# NUC1xx_registers register map
File version: 0.1
CPU: 
Registers are 32-bit, read-write, reset 0x0 unless marked. A register's access mark holds for its fields unless they carry their own. Offsets are from the block's base; [hi:lo] are bit positions; lines under a group give offsets from that group; {n}, {i} and the like mark numbered series.

## PDMA0 — Registers group
Base 0x50008000
Same registers: PDMA{n} {0x50008000+0x100*n} (n=1..8)
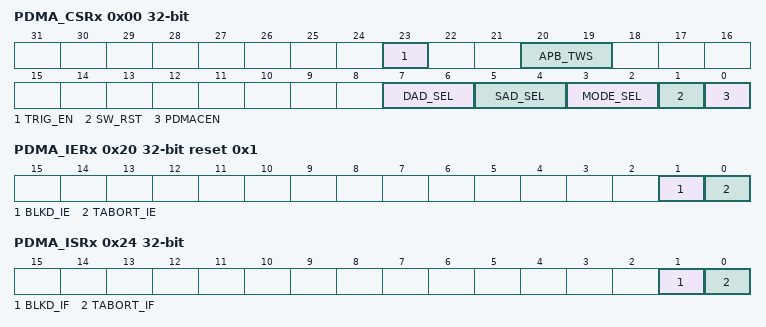
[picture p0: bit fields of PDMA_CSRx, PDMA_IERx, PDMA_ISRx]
0x00 PDMA_CSRx — PDMA Control and Status Register CHx
  [23] TRIG_EN — Trig_EN 0 = No effect. 1 = Enable PDMA data read or write transfer. Note: When PDMA transfer completed, this bit will be cleared automatically. If the bus error occurs, all PDMA transfer will be stopped. Software must reset all PDMA channel, and then trigger again.
  [20:19] APB_TWS — Peripheral transfer Width Select 00 = One word (32 bits) is transferred for every PDMA operation. 01 = One byte (8 bits) is transferred for every PDMA operation. 10 = One half-word (16 bits) is transferred for every PDMA operation. 11 = Reserved. Note: This field is meaningful only when MODE_SEL is IP to Memory mode (APB-to-Memory) or Memory to IP mode (Memory-to-APB).
  [7:6] DAD_SEL — Transfer Destination Address Direction Select 00 = Transfer Destination address is incremented successively. 01 = Reserved. 10 = Transfer Destination address is fixed (This feature can be used when data where transferred from multiple sources to a single destination). 11 = Reserved.
  [5:4] SAD_SEL — Transfer Source Address Direction Select 00 = Transfer Source address is incremented successively. 01 = Reserved. 10 = Transfer Source address is fixed (This feature can be used when data where transferred from a single source to multiple destinations). 11 = Reserved.
  [3:2] MODE_SEL — PDMA Mode Select 00 = Memory to Memory mode (Memory-to-Memory). 01 = IP to Memory mode (APB-to-Memory). 10 = Memory to IP mode (Memory-to-APB).
  [1] SW_RST — Software Engine Reset 0 = Writing 0 to this bit has no effect. 1 = Writing 1 to this bit will reset the internal state machine and pointers. The contents of control register will not be cleared. This bit will auto clear after few clock cycles.
  [0] PDMACEN — PDMA Channel Enable Setting this bit to 1 enables PDMA's operation. If this bit is cleared, PDMA will ignore all PDMA request and force Bus Master into IDLE state. Note: SW_RST(PDMA_CSRx[1], x= 0~8) will clear this bit.
0x04 PDMA_SARx — PDMA Transfer Source Address Register CHx
  [31:0] PDMA_SAR — PDMA Transfer Source Address Register This field indicates a 32-bit source address of PDMA. Note : The source address must be word alignment
0x08 PDMA_DARx — PDMA Transfer Destination Address Register CHx
  [31:0] PDMA_DAR — PDMA Transfer Destination Address Register This field indicates a 32-bit destination address of PDMA. Note : The destination address must be word alignment
0x0C PDMA_BCRx — PDMA Transfer Byte Count Register CHx
  [15:0] PDMA_BCR — PDMA Transfer Byte Count Register This field indicates a 16-bit transfer byte count of PDMA.it must be word alignment.
0x10 PDMA_POINTx ro — PDMA Internal Buffer Pointer Register CHx
  [3:0] PDMA_POINT — PDMA Internal Buffer Pointer Register (Read Only) This field indicates the internal buffer pointer.
0x14 PDMA_CSARx ro — PDMA Current Source Address Register CHx
  [31:0] PDMA_CSAR — PDMA Current Source Address Register (Read Only) This field indicates the source address where the PDMA transfer is just occurring.
0x18 PDMA_CDARx ro — PDMA Current Destination Address Register CHx
  [31:0] PDMA_CDAR — PDMA Current Destination Address Register (Read Only) This field indicates the destination address where the PDMA transfer is just occurring.
0x1C PDMA_CBCRx ro — PDMA Current Byte Count Register CHx
  [15:0] PDMA_CBCR — PDMA Current Byte Count Register (Read Only) This field indicates the current remained byte count of PDMA. Note : SW_RST will clear this register value.
0x20 PDMA_IERx reset 0x1 — PDMA Interrupt Enable Control Register CHx
  [1] BLKD_IE — PDMA Transfer Done Interrupt Enable 0 = Disable interrupt generator during PDMA transfer done. 1 = Enable interrupt generator during PDMA transfer done.
  [0] TABORT_IE — PDMA Read/Write Target Abort Interrupt Enable 0 = Disable target abort interrupt generation during PDMA transfer. 1 = Enable target abort interrupt generation during PDMA transfer.
0x24 PDMA_ISRx — PDMA Interrupt Status Register CHx
  [1] BLKD_IF write-1-clears — Block Transfer Done Interrupt Flag This bit indicates that PDMA has finished all transfer. 0 = Not finished yet. 1 = Done. NOTE: Software can write 1 to clear this bit to zero.
  [0] TABORT_IF write-1-clears — PDMA Read/Write Target Abort Interrupt Flag 0 = No bus ERROR response received. 1 = Bus ERROR response received. NOTE: Software can write 1 to clear this bit to zero.
0x80 PDMA_SBUF0_cx ro — PDMA Shared Buffer FIFO 0 Register CHx
  [31:0] PDMA_SBUF0 — PDMA Shared Buffer FIFO 0 (Read Only) Each channel has its own 1 word internal buffer.
